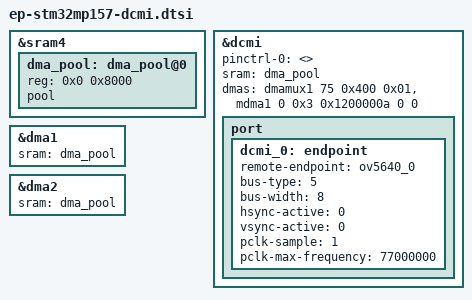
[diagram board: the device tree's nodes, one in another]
// SPDX-License-Identifier: (GPL-2.0+ OR BSD-3-Clause)
/*
 * Copyright (C) STMicroelectronics 2017 - All Rights Reserved
 * Author: Ludovic Barre <ludovic.barre@st.com> for STMicroelectronics.
 */
#include <dt-bindings/pinctrl/stm32-pinfunc.h>

&sram4 {
	dma_pool: dma_pool@0 {
		reg = <0x0 0x8000>;
		pool;
	};
};

&dcmi {
	status = "okay";
	pinctrl-names = "default";
	pinctrl-0 = <>;	
	
	/* Enable DMA-MDMA chaining by adding a SRAM pool and a MDMA channel */
	sram = <&dma_pool>;
	dmas = <&dmamux1 75 0x400 0x01>, <&mdma1 0 0x3 0x1200000a 0 0>;
	dma-names = "tx", "mdma_tx";

	port {
		dcmi_0: endpoint {
			remote-endpoint = <&ov5640_0>;
			bus-type = <5>;
			bus-width = <8>;
			hsync-active = <0>;
			vsync-active = <0>;
			pclk-sample = <1>;
			pclk-max-frequency = <77000000>;
		};
	};
};

&dma1 {
	sram = <&dma_pool>;
};

&dma2 {
	sram = <&dma_pool>;
};

